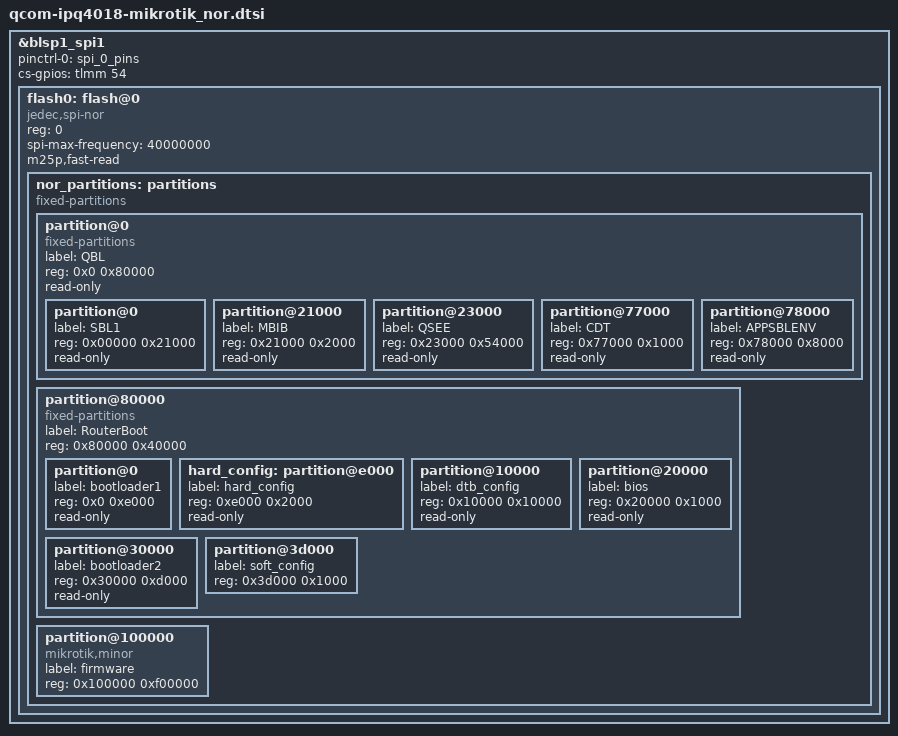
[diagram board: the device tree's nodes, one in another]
// SPDX-License-Identifier: GPL-2.0-or-later OR MIT
/* Copyright (c) 2020, Robert Marko <robimarko@gmail.com> */

#include "qcom-ipq4019.dtsi"
#include <dt-bindings/gpio/gpio.h>

&blsp1_spi1 {
	status = "okay";

	pinctrl-0 = <&spi_0_pins>;
	pinctrl-names = "default";
	cs-gpios = <&tlmm 54 GPIO_ACTIVE_HIGH>;

	flash0: flash@0 {
		reg = <0>;
		compatible = "jedec,spi-nor";
		spi-max-frequency = <40000000>;
		m25p,fast-read;

		nor_partitions: partitions {
			compatible = "fixed-partitions";
			#address-cells = <1>;
			#size-cells = <1>;

			partition@0 {
				compatible = "fixed-partitions";
				#address-cells = <1>;
				#size-cells = <1>;
				label = "QBL";
				reg = <0x0 0x80000>;
				read-only;

				partition@0 {
					label = "SBL1";
					reg = <0x00000 0x21000>;
					read-only;
				};

				partition@21000 {
					label = "MBIB";
					reg = <0x21000 0x2000>;
					read-only;
				};

				partition@23000 {
					label = "QSEE";
					reg = <0x23000 0x54000>;
					read-only;
				};

				partition@77000 {
					label = "CDT";
					reg = <0x77000 0x1000>;
					read-only;
				};

				partition@78000 {
					label = "APPSBLENV";
					reg = <0x78000 0x8000>;
					read-only;
				};
			};

			partition@80000 {
				compatible = "fixed-partitions";
				#address-cells = <1>;
				#size-cells = <1>;
				label = "RouterBoot";
				reg = <0x80000 0x40000>;

				partition@0 {
					label = "bootloader1";
					reg = <0x0 0xe000>;
					read-only;
				};

				hard_config: partition@e000 {
					label = "hard_config";
					reg = <0xe000 0x2000>;
					read-only;
				};

				partition@10000 {
					label = "dtb_config";
					reg = <0x10000 0x10000>;
					read-only;
				};

				partition@20000 {
					label = "bios";
					reg = <0x20000 0x1000>;
					read-only;
				};

				partition@30000 {
					label = "bootloader2";
					reg = <0x30000 0xd000>;
					read-only;
				};

				partition@3d000 {
					label = "soft_config";
					reg = <0x3d000 0x1000>;
				};
			};

			partition@100000 {
				compatible = "mikrotik,minor";
				label = "firmware";
				reg = <0x100000 0xf00000>;
			};
		};
	};
};
